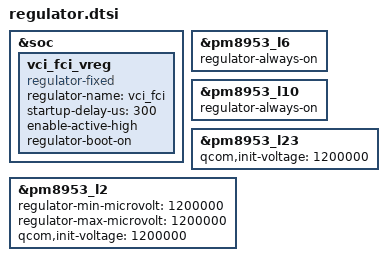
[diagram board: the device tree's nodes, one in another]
&soc {
	/delete-node/ adv_vreg;

	vci_fci_vreg: vci_fci_vreg {
		compatible = "regulator-fixed";
		regulator-name = "vci_fci";
		startup-delay-us = <300>;
		enable-active-high;
		regulator-boot-on;
	};
};

&pm8953_l6 {
	regulator-always-on;
};

&pm8953_l10 {
        regulator-always-on;
};

&pm8953_l23 {
        qcom,init-voltage = <1200000>;
};

&pm8953_l2 {
        regulator-min-microvolt = <1200000>;
        regulator-max-microvolt = <1200000>;
        qcom,init-voltage = <1200000>;
};
